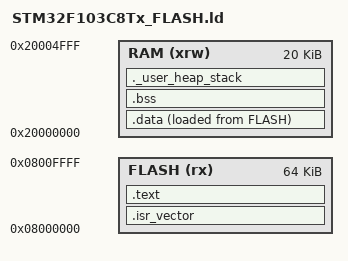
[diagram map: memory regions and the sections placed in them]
/*
 * Linker script for STM32F103C8T6 (P05 ECG Project)
 * Target: ARM Cortex-M3 (no FPU), 64KB Flash, 20KB SRAM
 * Zero-Heap Architecture (Heap size = 0, Stack = 2KB)
 */

ENTRY(Reset_Handler)

_estack = ORIGIN(RAM) + LENGTH(RAM); /* End of RAM */
_Min_Leftover_RAM = 0x400;           /* 1KB minimum reserve */
_Min_Stack_Size   = 0x800;           /* 2KB Stack size */
_Min_Heap_Size    = 0;               /* ZERO HEAP: No dynamic allocation */

MEMORY
{
  RAM   (xrw) : ORIGIN = 0x20000000, LENGTH = 20K
  FLASH (rx)  : ORIGIN = 0x08000000, LENGTH = 64K
}

SECTIONS
{
  .isr_vector :
  {
    . = ALIGN(4);
    KEEP(*(.isr_vector))
    . = ALIGN(4);
  } >FLASH

  .text :
  {
    . = ALIGN(4);
    *(.text)
    *(.text*)
    *(.rodata)
    *(.rodata*)
    *(.glue_7)
    *(.glue_7t)
    *(.eh_frame)
    KEEP (*(.init))
    KEEP (*(.fini))
    . = ALIGN(4);
    _etext = .;
  } >FLASH

  _sidata = LOADADDR(.data);

  .data :
  {
    . = ALIGN(4);
    _sdata = .;
    *(.data)
    *(.data*)
    . = ALIGN(4);
    _edata = .;
  } >RAM AT> FLASH

  .bss :
  {
    . = ALIGN(4);
    _sbss = .;
    __bss_start__ = _sbss;
    *(.bss)
    *(.bss*)
    *(COMMON)
    . = ALIGN(4);
    _ebss = .;
    __bss_end__ = _ebss;
  } >RAM

  ._user_heap_stack :
  {
    . = ALIGN(8);
    PROVIDE ( end = . );
    PROVIDE ( _end = . );
    . = . + _Min_Heap_Size;
    . = . + _Min_Stack_Size;
    . = ALIGN(8);
  } >RAM

  /DISCARD/ :
  {
    libc.a ( * )
    libm.a ( * )
    libgcc.a ( * )
  }
}
